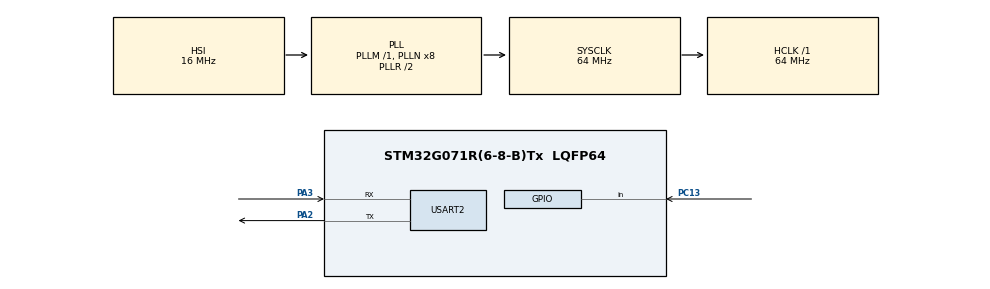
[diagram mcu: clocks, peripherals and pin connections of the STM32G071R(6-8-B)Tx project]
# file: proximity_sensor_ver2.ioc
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Mcu.Family=STM32G0
Mcu.Name=STM32G071R(6-8-B)Tx
Mcu.Package=LQFP64
PA13.Mode=Serial_Wire
PA13.Signal=SYS_SWDIO
PA14-BOOT0.Mode=Serial_Wire
PA14-BOOT0.Signal=SYS_SWCLK
PA2.Mode=Asynchronous
PA2.Signal=USART2_TX
PA3.Mode=Asynchronous
PA3.Signal=USART2_RX
PC13.GPIO_PuPd=GPIO_PULLUP
PC13.Signal=GPIO_Input
ProjectManager.HeapSize=0x200
ProjectManager.StackSize=0x400
ProjectManager.TargetToolchain=STM32CubeIDE
RCC.ADCFreq_Value=64000000
RCC.AHBFreq_Value=64000000
RCC.CortexFreq_Value=64000000
RCC.EXTERNAL_CLOCK_VALUE=12288000
RCC.HCLKFreq_Value=64000000
RCC.HSE_VALUE=8000000
RCC.HSI_VALUE=16000000
RCC.LSE_VALUE=32768
RCC.SYSCLKFreq_VALUE=64000000
RCC.SYSCLKSource=RCC_SYSCLKSOURCE_PLLCLK
RCC.VCOOutputFreq_Value=128000000
USART2.VirtualMode-Asynchronous=VM_ASYNC
VP_SYS_VS_DBSignals.Mode=DisableDeadBatterySignals
board=NUCLEO-G071RB

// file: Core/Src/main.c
/* USER CODE BEGIN Header */
/**
  ******************************************************************************
  * @file           : main.c
  * @brief          : Main program body
  ******************************************************************************
  * @attention
  *
  * Copyright (c) 2024 STMicroelectronics.
  * All rights reserved.
  *
  * This software is licensed under terms that can be found in the LICENSE file
  * in the root directory of this software component.
  * If no LICENSE file comes with this software, it is provided AS-IS.
  *
  ******************************************************************************
  */
/* USER CODE END Header */
#include "main.h"

/* USER CODE BEGIN Includes */
#include <stdio.h>
/* USER CODE END Includes */

UART_HandleTypeDef huart2;

/* USER CODE BEGIN PV */
uint8_t lastState = 0; // Variable to store the previous state
int r , f , count_zero , count_positive ;
uint32_t time_r , time_f , time_zero , time_positive , time_total , currentMillis , previousMillis;
uint32_t A , B , C ;
int z = 0;
double Duty ;
double water_use_total = 0;
double water_use_counter = 0;

/* USER CODE END PV */

void SystemClock_Config(void);
static void MX_GPIO_Init(void);
static void MX_USART2_UART_Init(void);
/* USER CODE BEGIN PFP */
void checkEdge(void); // Function to check for edges
/* USER CODE END PFP */

/* USER CODE BEGIN 0 */
int _write(int file, char *ptr, int len)
{
	HAL_UART_Transmit(&huart2,(uint8_t*)ptr,len,HAL_MAX_DELAY);
	return len;
}

/* USER CODE END 0 */

int main(void)
{

  /* MCU Configuration--------------------------------------------------------*/

  /* Reset of all peripherals, Initializes the Flash interface and the Systick. */
  HAL_Init();

  /* Configure the system clock */
  SystemClock_Config();

  /* Initialize all configured peripherals */
  MX_GPIO_Init();
  MX_USART2_UART_Init();
  /* USER CODE BEGIN 2 */

  lastState = HAL_GPIO_ReadPin(GPIOC, GPIO_PIN_13); // Read the last state of PC13

  /* USER CODE END 2 */

  /* Infinite loop */
  /* USER CODE BEGIN WHILE */
  while (1)
  {
	  currentMillis = HAL_GetTick();

	  checkEdge(); // Call the function to check for edges
	  //...........................................................................................

	  if( r == 1 && f ==1){

		  ///////////////////////////////////////////////////////////////////////
		  if(time_f > time_r){

			  time_zero = time_f - time_r ;

			  if(z != 1){
				  	 printf("Time_zero : %ld ms \n\r",time_zero);
			  }
			  count_zero = 1;

			  r = 0;

		  } else if( time_r > time_f){
			  time_positive = time_r - time_f;

			  if(z != 1){
				  	 printf("Time_positive : %ld ms \n\r",time_positive);
			  }
			  count_positive = 1;

			  f = 0;
		  }
		  ///////////////////////////////////////////////////////////////////////////////////////////

		  if(count_positive == 1 && count_zero == 1){

			  if( z != 1){
				  time_total = time_positive + time_zero;
				  printf("time_total : %ld ms \n\r" , time_total);

				  if(time_total > 0 && time_total <= 1500){
					  printf("speed level 1\n\r");
				  }else if (time_total > 1500 && time_total <= 2500){
					  printf("speed level 2\n\r");
				  }else {
					  printf("speed level 3\n\r");
				  }

				  A = time_positive * 1000;
				  B = time_zero * 1000;
				  C = time_total * 1000;

				  Duty = ((double)A / (double)C ) * 100;
				  printf("Duty : %.3lf \n\r" , Duty);

				  water_use_counter++;
				  printf("water use counter (Low) : %.3lf L \n\r", (water_use_counter - 1.000) + ((double)B / (double)C ));

			  }

			  printf("water use counter (total) : %.3lf L \n\r" , water_use_counter);

			  water_use_total = (water_use_counter) / 1000.000;
			  printf("water use total : %.4lf m^3 \n\r" , water_use_total);

			  printf("---------------\n\r");
			  count_zero = 0;
			  count_positive = 0;
			  z=0;

			  time_zero = 0;
			  time_positive = 0;

		  }

		  ////////////////////////////////////////////////////////////////////////////////////////
		  previousMillis = HAL_GetTick();

		  }else if(currentMillis - previousMillis >= 10000){
			  previousMillis = currentMillis ;

			  printf("water is not running \n\r");

			  if((r == 1 || f == 1) && z ==1){
				  water_use_counter += 0.5;

				  r = 2;
				  f = 2;

			  }

			  z = 1;
		  }
	  //.................................................................................................
    /* USER CODE END WHILE */

  }
}

void SystemClock_Config(void)
{
  RCC_OscInitTypeDef RCC_OscInitStruct = {0};
  RCC_ClkInitTypeDef RCC_ClkInitStruct = {0};

  /** Configure the main internal regulator output voltage
  */
  HAL_PWREx_ControlVoltageScaling(PWR_REGULATOR_VOLTAGE_SCALE1);

  /** Initializes the RCC Oscillators according to the specified parameters
  * in the RCC_OscInitTypeDef structure.
  */
  RCC_OscInitStruct.OscillatorType = RCC_OSCILLATORTYPE_HSI;
  RCC_OscInitStruct.HSIState = RCC_HSI_ON;
  RCC_OscInitStruct.HSIDiv = RCC_HSI_DIV1;
  RCC_OscInitStruct.HSICalibrationValue = RCC_HSICALIBRATION_DEFAULT;
  RCC_OscInitStruct.PLL.PLLState = RCC_PLL_ON;
  RCC_OscInitStruct.PLL.PLLSource = RCC_PLLSOURCE_HSI;
  RCC_OscInitStruct.PLL.PLLM = RCC_PLLM_DIV1;
  RCC_OscInitStruct.PLL.PLLN = 8;
  RCC_OscInitStruct.PLL.PLLP = RCC_PLLP_DIV2;
  RCC_OscInitStruct.PLL.PLLQ = RCC_PLLQ_DIV2;
  RCC_OscInitStruct.PLL.PLLR = RCC_PLLR_DIV2;
  if (HAL_RCC_OscConfig(&RCC_OscInitStruct) != HAL_OK)
  {
    Error_Handler();
  }

  /** Initializes the CPU, AHB and APB buses clocks
  */
  RCC_ClkInitStruct.ClockType = RCC_CLOCKTYPE_HCLK|RCC_CLOCKTYPE_SYSCLK
                              |RCC_CLOCKTYPE_PCLK1;
  RCC_ClkInitStruct.SYSCLKSource = RCC_SYSCLKSOURCE_PLLCLK;
  RCC_ClkInitStruct.AHBCLKDivider = RCC_SYSCLK_DIV1;
  RCC_ClkInitStruct.APB1CLKDivider = RCC_HCLK_DIV1;

  if (HAL_RCC_ClockConfig(&RCC_ClkInitStruct, FLASH_LATENCY_2) != HAL_OK)
  {
    Error_Handler();
  }
}

static void MX_USART2_UART_Init(void)
{

  huart2.Instance = USART2;
  huart2.Init.BaudRate = 115200;
  huart2.Init.WordLength = UART_WORDLENGTH_8B;
  huart2.Init.StopBits = UART_STOPBITS_1;
  huart2.Init.Parity = UART_PARITY_NONE;
  huart2.Init.Mode = UART_MODE_TX_RX;
  huart2.Init.HwFlowCtl = UART_HWCONTROL_NONE;
  huart2.Init.OverSampling = UART_OVERSAMPLING_16;
  huart2.Init.OneBitSampling = UART_ONE_BIT_SAMPLE_DISABLE;
  huart2.Init.ClockPrescaler = UART_PRESCALER_DIV1;
  huart2.AdvancedInit.AdvFeatureInit = UART_ADVFEATURE_NO_INIT;
  if (HAL_UART_Init(&huart2) != HAL_OK)
  {
    Error_Handler();
  }
  if (HAL_UARTEx_SetTxFifoThreshold(&huart2, UART_TXFIFO_THRESHOLD_1_8) != HAL_OK)
  {
    Error_Handler();
  }
  if (HAL_UARTEx_SetRxFifoThreshold(&huart2, UART_RXFIFO_THRESHOLD_1_8) != HAL_OK)
  {
    Error_Handler();
  }
  if (HAL_UARTEx_DisableFifoMode(&huart2) != HAL_OK)
  {
    Error_Handler();
  }

}

static void MX_GPIO_Init(void)
{
  GPIO_InitTypeDef GPIO_InitStruct = {0};

  /* GPIO Ports Clock Enable */
  __HAL_RCC_GPIOC_CLK_ENABLE();
  __HAL_RCC_GPIOA_CLK_ENABLE();

  /*Configure GPIO pin : PC13 */
  GPIO_InitStruct.Pin = GPIO_PIN_13;
  GPIO_InitStruct.Mode = GPIO_MODE_INPUT;
  GPIO_InitStruct.Pull = GPIO_PULLUP;
  HAL_GPIO_Init(GPIOC, &GPIO_InitStruct);

}

/* USER CODE BEGIN 4 */
void checkEdge(void) {

    uint8_t currentState = HAL_GPIO_ReadPin(GPIOC, GPIO_PIN_13); // Read the current state of PC13

    if (currentState == GPIO_PIN_SET && lastState == GPIO_PIN_RESET) {
        // Rising edge detected
        //printf("Detected rising edge on PC13!\n");

    	r = 1;
    	time_r = HAL_GetTick();

    } else if (currentState == GPIO_PIN_RESET && lastState == GPIO_PIN_SET) {
        // Falling edge detected
        //printf("Detected falling edge on PC13!\n");

    	f = 1 ;
    	time_f = HAL_GetTick();
    }

    lastState = currentState; // Update lastState to the current state
}
/* USER CODE END 4 */

void Error_Handler(void)
{
  __disable_irq();
  while (1)
  {
  }
}
